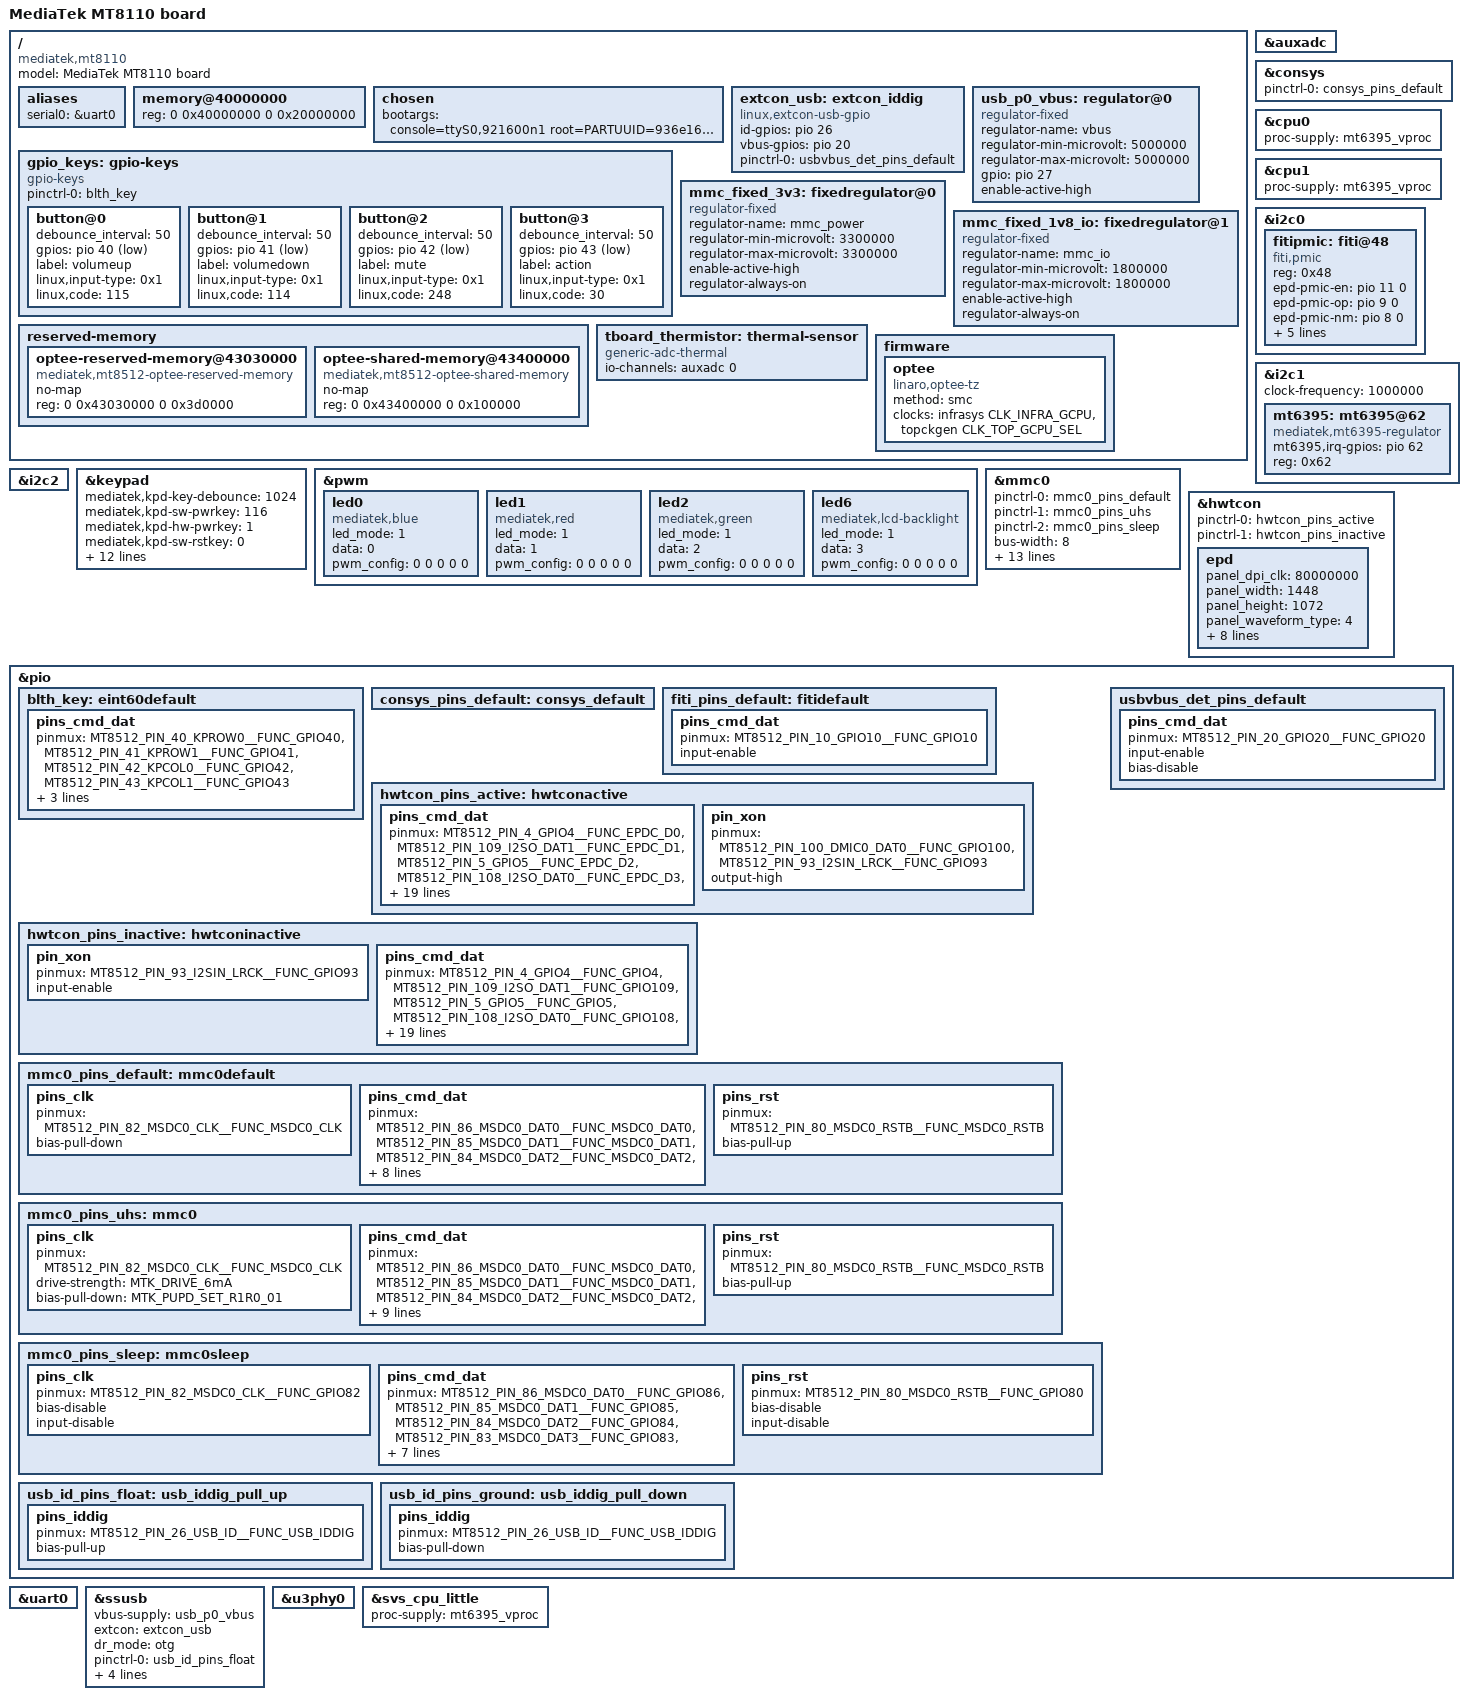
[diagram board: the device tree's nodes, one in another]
/*
 * Copyright (c) 2019 MediaTek Inc.
 *
 * SPDX-License-Identifier: (GPL-2.0 OR MIT)
 */

/dts-v1/;
#include "mt8110.dtsi"

/ {
	model = "MediaTek MT8110 board";
	compatible = "mediatek,mt8110", "mediatek,mt8512";

	aliases {
		serial0 = &uart0;
	};

	memory@40000000 {
		device_type = "memory";
		reg = <0 0x40000000 0 0x20000000>;
	};
	chosen {
		bootargs = "console=ttyS0,921600n1 \
		root=PARTUUID=936e1662-2b63-435d-859d-1b9e5a838335 \
		rootwait skip_initramfs \
		earlycon=uart8250,mmio32,0x11002000 \
		initcall_debug androidboot.hardware=mt8512 \
		firmware_class.path=/vendor/firmware";
	};
	extcon_usb: extcon_iddig {
		compatible = "linux,extcon-usb-gpio";
		id-gpios = <&pio 26 0>;
		vbus-gpios = <&pio 20 0>;
		pinctrl-names = "default";
		pinctrl-0 = <&usbvbus_det_pins_default>;
	};

		usb_p0_vbus: regulator@0 {
		compatible = "regulator-fixed";
		regulator-name = "vbus";
		regulator-min-microvolt = <5000000>;
		regulator-max-microvolt = <5000000>;
		gpio = <&pio 27 0>;
		enable-active-high;
	};

	gpio_keys: gpio-keys {
		compatible = "gpio-keys";
		pinctrl-names = "default";
		pinctrl-0 = <&blth_key>;
		status = "okay";

		button@0 {
			debounce_interval = <50>;
			gpios = <&pio 40 1>;
			label = "volumeup";
			linux,input-type = <0x1>;
			linux,code = <115>;
		};

		button@1 {
			debounce_interval = <50>;
			gpios = <&pio 41 1>;
			label = "volumedown";
			linux,input-type = <0x1>;
			linux,code = <114>;
		};

		button@2 {
			debounce_interval = <50>;
			gpios = <&pio 42 1>;
			label = "mute";
			linux,input-type = <0x1>;
			linux,code = <248>;
		};

		button@3 {
			debounce_interval = <50>;
			gpios = <&pio 43 1>;
			label = "action";
			linux,input-type = <0x1>;
			linux,code = <30>;
		};
	};

	mmc_fixed_3v3: fixedregulator@0 {
		compatible = "regulator-fixed";
		regulator-name = "mmc_power";
		regulator-min-microvolt = <3300000>;
		regulator-max-microvolt = <3300000>;
		enable-active-high;
		regulator-always-on;
	};

	mmc_fixed_1v8_io: fixedregulator@1 {
		compatible = "regulator-fixed";
		regulator-name = "mmc_io";
		regulator-min-microvolt = <1800000>;
		regulator-max-microvolt = <1800000>;
		enable-active-high;
		regulator-always-on;
	};

	reserved-memory {
		optee-reserved-memory@43030000 {
			compatible = "mediatek,mt8512-optee-reserved-memory";
			no-map;
			reg = <0 0x43030000 0 0x3d0000>;
		};
		optee-shared-memory@43400000 {
			compatible = "mediatek,mt8512-optee-shared-memory";
			no-map;
			reg = <0 0x43400000 0 0x100000>;
		};
	};

	tboard_thermistor: thermal-sensor {
		compatible = "generic-adc-thermal";
		#thermal-sensor-cells = <0>;
		io-channels = <&auxadc 0>;
		io-channel-names = "sensor-channel";
	};

	firmware {
		optee {
			compatible = "linaro,optee-tz";
			method = "smc";
			clocks = <&infrasys CLK_INFRA_GCPU>,
				 <&topckgen CLK_TOP_GCPU_SEL>;
			clock-names = "GCPU",
				      "GCPU_B";
		};
	};
};

&auxadc {
	status = "okay";
};

&consys {
	pinctrl-names = "default";
	pinctrl-0 = <&consys_pins_default>;
	status = "okay";
};

&cpu0 {
	proc-supply = <&mt6395_vproc>;
};

&cpu1 {
	proc-supply = <&mt6395_vproc>;
};

&i2c0 {
	status = "okay";
	fitipmic: fiti@48 {
		compatible = "fiti,pmic";
		reg = <0x48>;
		epd-pmic-en = <&pio 11 0>;
		epd-pmic-op = <&pio 9 0>;
		epd-pmic-nm = <&pio 8 0>;
		interrupt-parent = <&pio>;
		interrupts = <10 IRQ_TYPE_LEVEL_HIGH>;
		deb-gpios = <&pio 5 0>;
		debounce = <16>;
		pinctrl-names = "default";
		pinctrl-0 = <&fiti_pins_default>;
		status = "okay";
	};
};

&i2c1 {
	status = "okay";
	clock-frequency = <1000000>;

	mt6395: mt6395@62 {
		compatible = "mediatek,mt6395-regulator";
		mt6395,irq-gpios = <&pio 62 0x0>;
		reg = <0x62>;
		status = "okay";
	};
};

&i2c2 {
	status = "okay";
};

&keypad {
	status = "okay";
	mediatek,kpd-key-debounce = <1024>;
	mediatek,kpd-sw-pwrkey = <116>;
	mediatek,kpd-hw-pwrkey = <1>;
	mediatek,kpd-sw-rstkey  = <0>;
	mediatek,kpd-hw-rstkey = <3>;
	mediatek,kpd-use-extend-type = <0>;
	/*HW Keycode [0~3] -> Linux Keycode*/
	mediatek,kpd-hw-map-num = <72>;
	mediatek,kpd-hw-init-map =
			<0 0 0 0 0 0 0 0 0 0 0 0 0
			 0 0 0 0 0 0 0 0 0 0 0 0 0 0 0 0 0 0 0 0 0 0 0 0
			 0 0 0 0 0 0 0 0 0 0 0 0 0 0 0 0 0 0 0 0 0 0 0 0
			 0 0 0 0 0 0 0 0 0 0 0 >;
	mediatek,kpd-pwrkey-eint-gpio = <0>;
	mediatek,kpd-pwkey-gpio-din  = <0>;
	mediatek,kpd-hw-dl-key0 = <0>;
	mediatek,kpd-hw-dl-key1 = <3>;
	mediatek,kpd-hw-dl-key2 = <1>;
	mediatek,kpd-hw-recovery-key = <0>;
	mediatek,kpd-hw-factory-key  = <3>;
};

&pwm {
	status = "okay";
	/* led part */
	led0 {
		compatible = "mediatek,blue";
		led_mode = <1>;
		data = <0>;
		pwm_config = <0 0 0 0 0>;
	};

	led1 {
		compatible = "mediatek,red";
		led_mode = <1>;
		data = <1>;
		pwm_config = <0 0 0 0 0>;
	};

	led2 {
		compatible = "mediatek,green";
		led_mode = <1>;
		data = <2>;
		pwm_config = <0 0 0 0 0>;
	};
	led6 {
		compatible = "mediatek,lcd-backlight";
		led_mode = <1>;
		data = <3>;
		pwm_config = <0 0 0 0 0>;
	};
};

&mmc0 {
	status = "okay";
	pinctrl-names = "default", "state_uhs", "sleep";
	pinctrl-0 = <&mmc0_pins_default>;
	pinctrl-1 = <&mmc0_pins_uhs>;
	pinctrl-2 = <&mmc0_pins_sleep>;
	bus-width = <8>;
	max-frequency = <200000000>;
	cap-mmc-highspeed;
	mmc-hs200-1_8v;
	cap-cqe;
	cap-cqe_dcmd;
	vmmc-supply = <&mmc_fixed_3v3>;
	vqmmc-supply = <&mmc_fixed_1v8_io>;
	assigned-clocks = <&topckgen CLK_TOP_MSDC50_0_SEL>;
	assigned-clock-parents = <&topckgen CLK_TOP_MSDCPLL_D2>;
	non-removable;
	no-sd;
	no-sdio;
};

&hwtcon {
	status = "okay";
	pinctrl-names = "active","inactive";
	pinctrl-0 = <&hwtcon_pins_active>;
	pinctrl-1 = <&hwtcon_pins_inactive>;
	epd{
		panel_dpi_clk = <80000000>;
		panel_width = <1448>;
		panel_height = <1072>;
		panel_waveform_type = <4>;
		panel_output_8bit = <1>;
		panel_tcon0 = <7 1079 51 64 0 1 0 0>;
		panel_tcon1 = <8 1080 7 35 0 0 0 0>;
		panel_tcon2 = <0 0 0 0 0 0 0 0>;
		panel_tcon3 = <1 1081 235 797 0 0 0 0>;
		panel_tcon4 = <0 0 0 0 0 0 0 0>;
		panel_tcon5 = <2 3 512 592 4 1 1 7>;
		panel_dpi = <14 51 8 2 4 4 0>;
		status = "okay";
	};
};

&pio {
	pinctrl-names = "default";

	blth_key: eint60default {
		pins_cmd_dat {
			pinmux = <MT8512_PIN_40_KPROW0__FUNC_GPIO40>,
				<MT8512_PIN_41_KPROW1__FUNC_GPIO41>,
				<MT8512_PIN_42_KPCOL0__FUNC_GPIO42>,
				<MT8512_PIN_43_KPCOL1__FUNC_GPIO43>;
			slew-rate = <0>;
			bias-pull-up = <MTK_PUPD_SET_R1R0_01>;
			input-enable;
		};
	};

	consys_pins_default: consys_default {
	};

	fiti_pins_default: fitidefault {
		pins_cmd_dat {
			pinmux = <MT8512_PIN_10_GPIO10__FUNC_GPIO10>;
			input-enable;
		};
	};

	hwtcon_pins_active: hwtconactive {
		pins_cmd_dat {
			pinmux = <MT8512_PIN_4_GPIO4__FUNC_EPDC_D0>,
				 <MT8512_PIN_109_I2SO_DAT1__FUNC_EPDC_D1>,
				 <MT8512_PIN_5_GPIO5__FUNC_EPDC_D2>,
				 <MT8512_PIN_108_I2SO_DAT0__FUNC_EPDC_D3>,
				 <MT8512_PIN_6_GPIO6__FUNC_EPDC_D4>,
				 <MT8512_PIN_105_I2SO_BCK__FUNC_EPDC_D5>,
				 <MT8512_PIN_98_I2SIN_DAT3__FUNC_EPDC_D6>,
				 <MT8512_PIN_106_I2SO_LRCK__FUNC_EPDC_D7>,
				 <MT8512_PIN_97_I2SIN_DAT2__FUNC_EPDC_D8>,
				 <MT8512_PIN_87_SPDIF__FUNC_EPDC_D9>,
				 <MT8512_PIN_96_I2SIN_DAT1__FUNC_EPDC_D10>,
				 <MT8512_PIN_2_GPIO2__FUNC_EPDC_D11>,
				 <MT8512_PIN_95_I2SIN_DAT0__FUNC_EPDC_D12>,
				 <MT8512_PIN_3_GPIO3__FUNC_EPDC_D13>,
				 <MT8512_PIN_101_DMIC0_DAT1__FUNC_EPDC_D14>,
				 <MT8512_PIN_92_I2SIN_MCLK__FUNC_EPDC_D15>,
				 <MT8512_PIN_7_GPIO7__FUNC_EPDC_SDOE>,
				 <MT8512_PIN_94_I2SIN_BCK__FUNC_EPDC_GDSP>,
				 <MT8512_PIN_99_DMIC0_CLK__FUNC_EPDC_GDCLK>,
				 <MT8512_PIN_107_I2SO_MCLK__FUNC_EPDC_SDCLK>,
				 <MT8512_PIN_110_I2SO_DAT2__FUNC_EPDC_SDCE0>,
				 <MT8512_PIN_111_I2SO_DAT3__FUNC_EPDC_SDLE>;
				output-low;
		};

		pin_xon {
			pinmux = <MT8512_PIN_100_DMIC0_DAT0__FUNC_GPIO100>,
				 <MT8512_PIN_93_I2SIN_LRCK__FUNC_GPIO93>;
				 output-high;
		};
	};

	hwtcon_pins_inactive: hwtconinactive {
		pin_xon {
			pinmux = <MT8512_PIN_93_I2SIN_LRCK__FUNC_GPIO93>;
				 input-enable;
		};

		pins_cmd_dat {
			pinmux = <MT8512_PIN_4_GPIO4__FUNC_GPIO4>,
				 <MT8512_PIN_109_I2SO_DAT1__FUNC_GPIO109>,
				 <MT8512_PIN_5_GPIO5__FUNC_GPIO5>,
				 <MT8512_PIN_108_I2SO_DAT0__FUNC_GPIO108>,
				 <MT8512_PIN_6_GPIO6__FUNC_GPIO6>,
				 <MT8512_PIN_105_I2SO_BCK__FUNC_GPIO105>,
				 <MT8512_PIN_98_I2SIN_DAT3__FUNC_GPIO98>,
				 <MT8512_PIN_106_I2SO_LRCK__FUNC_GPIO106>,
				 <MT8512_PIN_97_I2SIN_DAT2__FUNC_GPIO97>,
				 <MT8512_PIN_87_SPDIF__FUNC_GPIO87>,
				 <MT8512_PIN_96_I2SIN_DAT1__FUNC_GPIO96>,
				 <MT8512_PIN_2_GPIO2__FUNC_GPIO2>,
				 <MT8512_PIN_95_I2SIN_DAT0__FUNC_GPIO95>,
				 <MT8512_PIN_3_GPIO3__FUNC_GPIO3>,
				 <MT8512_PIN_101_DMIC0_DAT1__FUNC_GPIO101>,
				 <MT8512_PIN_92_I2SIN_MCLK__FUNC_GPIO92>,
				 <MT8512_PIN_7_GPIO7__FUNC_GPIO7>,
				 <MT8512_PIN_94_I2SIN_BCK__FUNC_GPIO94>,
				 <MT8512_PIN_99_DMIC0_CLK__FUNC_GPIO99>,
				 <MT8512_PIN_107_I2SO_MCLK__FUNC_GPIO107>,
				 <MT8512_PIN_110_I2SO_DAT2__FUNC_GPIO110>,
				 <MT8512_PIN_111_I2SO_DAT3__FUNC_GPIO111>;
				input-enable;
		};
	};

	mmc0_pins_default: mmc0default {
		pins_clk {
			pinmux = <MT8512_PIN_82_MSDC0_CLK__FUNC_MSDC0_CLK>;
			bias-pull-down;
		};

		pins_cmd_dat {
			pinmux = <MT8512_PIN_86_MSDC0_DAT0__FUNC_MSDC0_DAT0>,
				 <MT8512_PIN_85_MSDC0_DAT1__FUNC_MSDC0_DAT1>,
				 <MT8512_PIN_84_MSDC0_DAT2__FUNC_MSDC0_DAT2>,
				 <MT8512_PIN_83_MSDC0_DAT3__FUNC_MSDC0_DAT3>,
				 <MT8512_PIN_79_MSDC0_DAT4__FUNC_MSDC0_DAT4>,
				 <MT8512_PIN_78_MSDC0_DAT5__FUNC_MSDC0_DAT5>,
				 <MT8512_PIN_77_MSDC0_DAT6__FUNC_MSDC0_DAT6>,
				 <MT8512_PIN_76_MSDC0_DAT7__FUNC_MSDC0_DAT7>,
				 <MT8512_PIN_81_MSDC0_CMD__FUNC_MSDC0_CMD>;
			input-enable;
			bias-pull-up;
		};

		pins_rst {
			pinmux = <MT8512_PIN_80_MSDC0_RSTB__FUNC_MSDC0_RSTB>;
			bias-pull-up;
		};
	};

	mmc0_pins_uhs: mmc0 {
		pins_clk {
			pinmux = <MT8512_PIN_82_MSDC0_CLK__FUNC_MSDC0_CLK>;
			drive-strength = <MTK_DRIVE_6mA>;
			bias-pull-down = <MTK_PUPD_SET_R1R0_01>;
		};

		pins_cmd_dat {
			pinmux = <MT8512_PIN_86_MSDC0_DAT0__FUNC_MSDC0_DAT0>,
				 <MT8512_PIN_85_MSDC0_DAT1__FUNC_MSDC0_DAT1>,
				 <MT8512_PIN_84_MSDC0_DAT2__FUNC_MSDC0_DAT2>,
				 <MT8512_PIN_83_MSDC0_DAT3__FUNC_MSDC0_DAT3>,
				 <MT8512_PIN_79_MSDC0_DAT4__FUNC_MSDC0_DAT4>,
				 <MT8512_PIN_78_MSDC0_DAT5__FUNC_MSDC0_DAT5>,
				 <MT8512_PIN_77_MSDC0_DAT6__FUNC_MSDC0_DAT6>,
				 <MT8512_PIN_76_MSDC0_DAT7__FUNC_MSDC0_DAT7>,
				 <MT8512_PIN_81_MSDC0_CMD__FUNC_MSDC0_CMD>;
			input-enable;
			drive-strength = <MTK_DRIVE_6mA>;
			bias-pull-up = <MTK_PUPD_SET_R1R0_01>;
		};

		pins_rst {
			pinmux = <MT8512_PIN_80_MSDC0_RSTB__FUNC_MSDC0_RSTB>;
			bias-pull-up;
		};
	};

	mmc0_pins_sleep: mmc0sleep {
		pins_clk {
			pinmux = <MT8512_PIN_82_MSDC0_CLK__FUNC_GPIO82>;
			bias-disable;
			input-disable;
		};

		pins_cmd_dat {
			pinmux = <MT8512_PIN_86_MSDC0_DAT0__FUNC_GPIO86>,
				 <MT8512_PIN_85_MSDC0_DAT1__FUNC_GPIO85>,
				 <MT8512_PIN_84_MSDC0_DAT2__FUNC_GPIO84>,
				 <MT8512_PIN_83_MSDC0_DAT3__FUNC_GPIO83>,
				 <MT8512_PIN_79_MSDC0_DAT4__FUNC_GPIO79>,
				 <MT8512_PIN_78_MSDC0_DAT5__FUNC_GPIO78>,
				 <MT8512_PIN_77_MSDC0_DAT6__FUNC_GPIO77>,
				 <MT8512_PIN_76_MSDC0_DAT7__FUNC_GPIO76>,
				 <MT8512_PIN_81_MSDC0_CMD__FUNC_GPIO81>;
			bias-disable;
			input-disable;
		};

		pins_rst {
			pinmux = <MT8512_PIN_80_MSDC0_RSTB__FUNC_GPIO80>;
			bias-disable;
			input-disable;
		};
	};

	usb_id_pins_float: usb_iddig_pull_up {
		pins_iddig {
			pinmux = <MT8512_PIN_26_USB_ID__FUNC_USB_IDDIG>;
			bias-pull-up;
		};
	};

	usb_id_pins_ground: usb_iddig_pull_down {
		pins_iddig {
			pinmux = <MT8512_PIN_26_USB_ID__FUNC_USB_IDDIG>;
			bias-pull-down;
		};
	};
	usbvbus_det_pins_default: usbvbus_det_pins_default {
		pins_cmd_dat {
			pinmux = <MT8512_PIN_20_GPIO20__FUNC_GPIO20>;
			input-enable;
			bias-disable;
		};
	};
};

&uart0 {
	status = "okay";
};

&ssusb {
	vbus-supply = <&usb_p0_vbus>;
	extcon = <&extcon_usb>;
	dr_mode = "otg";
	pinctrl-names = "default", "id_float", "id_ground";
	pinctrl-0 = <&usb_id_pins_float>;
	pinctrl-1 = <&usb_id_pins_float>;
	pinctrl-2 = <&usb_id_pins_ground>;
	phys = <&u2port0 PHY_TYPE_USB2>;
	mediatek,force_vbus = "true";
	status="okay";
};

&u3phy0 {
	status = "okay";
};

&svs_cpu_little {
	proc-supply = <&mt6395_vproc>;
};

#include "mt6395.dtsi"
